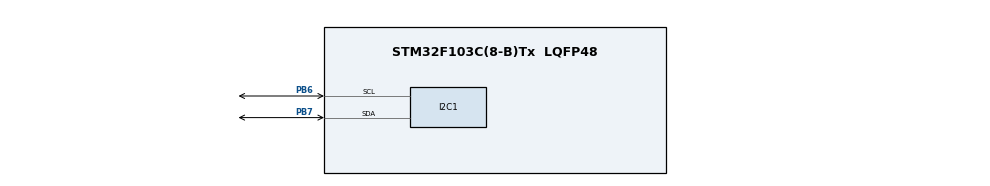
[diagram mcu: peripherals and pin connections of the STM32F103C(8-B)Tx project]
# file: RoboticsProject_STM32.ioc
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Mcu.Family=STM32F1
Mcu.Name=STM32F103C(8-B)Tx
Mcu.Package=LQFP48
NVIC.PriorityGroup=NVIC_PRIORITYGROUP_4
PA13.Mode=Serial_Wire
PA13.Signal=SYS_JTMS-SWDIO
PA14.Mode=Serial_Wire
PA14.Signal=SYS_JTCK-SWCLK
PB6.Mode=I2C
PB6.Signal=I2C1_SCL
PB7.Mode=I2C
PB7.Signal=I2C1_SDA
PD0-OSC_IN.Mode=HSE-External-Oscillator
PD0-OSC_IN.Signal=RCC_OSC_IN
PD1-OSC_OUT.Mode=HSE-External-Oscillator
PD1-OSC_OUT.Signal=RCC_OSC_OUT
ProjectManager.HeapSize=0x200
ProjectManager.StackSize=0x400
ProjectManager.TargetToolchain=STM32CubeIDE
RCC.APB1Freq_Value=8000000
RCC.APB2Freq_Value=8000000
board=custom

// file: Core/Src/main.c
/* USER CODE BEGIN Header */
/**
  ******************************************************************************
  * @file           : main.c
  * @brief          : Main program body
  ******************************************************************************
  * @attention
  *
  * Copyright (c) 2024 STMicroelectronics.
  * All rights reserved.
  *
  * This software is licensed under terms that can be found in the LICENSE file
  * in the root directory of this software component.
  * If no LICENSE file comes with this software, it is provided AS-IS.
  *
  ******************************************************************************
  */
/* USER CODE END Header */
/* USER CODE BEGIN Header */
/**
  ******************************************************************************
  * @file           : main.c
  * @brief          : Main program body
  ******************************************************************************
  * @attention
  *
  * Copyright (c) 2024 STMicroelectronics.
  * All rights reserved.
  *
  * This software is licensed under terms that can be found in the LICENSE file
  * in the root directory of this software component.
  * If no LICENSE file comes with this software, it is provided AS-IS.
  *
  ******************************************************************************
  */
/* USER CODE END Header */
#include "main.h"
#include <math.h>

/* USER CODE BEGIN PD */
#define PCA9685_ADDRESS 0x80
#define MPU6050_ADDR 0xD0
#define PCA9685_MODE1 0x00
#define PCA9685_PRE_SCALE 0xFE
#define PCA9685_LED0_ON_L 0x06
#define PCA9685_MODE1_SLEEP_BIT 4
#define PCA9685_MODE1_AI_BIT 5
#define PCA9685_MODE1_RESTART_BIT 7
#define NUM_SERVOS 5
/* USER CODE END PD */

I2C_HandleTypeDef hi2c1;
float Ax, Ay, Az, Gz;

void SystemClock_Config(void);
static void MX_GPIO_Init(void);
static void MX_I2C1_Init(void);

/* USER CODE BEGIN PFP */

void PCA9685_SetBit(uint8_t Register, uint8_t Bit, uint8_t Value);
void PCA9685_SetPWMFrequency(uint16_t frequency);
void PCA9685_Init(uint16_t frequency);
void PCA9685_SetPWM(uint8_t Channel, uint16_t OnTime, uint16_t OffTime);
void PCA9685_SetServoAngle(uint8_t Channel, float Angle);
void MPU6050_Init(void);
void MPU6050_Read_Accel(void);
void MPU6050_Read_Gyro(void);

/* USER CODE END PFP */

/* USER CODE BEGIN 0 */

void PCA9685_SetBit(uint8_t Register, uint8_t Bit, uint8_t Value)
{
    uint8_t readValue;
    HAL_I2C_Mem_Read(&hi2c1, PCA9685_ADDRESS, Register, 1, &readValue, 1, 10);
    if (Value == 0)
        readValue &= ~(1 << Bit);
    else
        readValue |= (1 << Bit);
    HAL_I2C_Mem_Write(&hi2c1, PCA9685_ADDRESS, Register, 1, &readValue, 1, 10);
    HAL_Delay(1);
}

void PCA9685_SetPWMFrequency(uint16_t frequency)
{
    uint8_t prescale = (uint8_t)((25000000 / (4096 * frequency)) - 1);
    PCA9685_SetBit(PCA9685_MODE1, PCA9685_MODE1_SLEEP_BIT, 1);
    HAL_I2C_Mem_Write(&hi2c1, PCA9685_ADDRESS, PCA9685_PRE_SCALE, 1, &prescale, 1, 10);
    PCA9685_SetBit(PCA9685_MODE1, PCA9685_MODE1_SLEEP_BIT, 0);
    PCA9685_SetBit(PCA9685_MODE1, PCA9685_MODE1_RESTART_BIT, 1);
}

void PCA9685_Init(uint16_t frequency)
{
    PCA9685_SetPWMFrequency(frequency);
    PCA9685_SetBit(PCA9685_MODE1, PCA9685_MODE1_AI_BIT, 1);
}

void PCA9685_SetPWM(uint8_t Channel, uint16_t OnTime, uint16_t OffTime)
{
    uint8_t registerAddress = PCA9685_LED0_ON_L + (4 * Channel);
    uint8_t pwm[4] = { OnTime & 0xFF, OnTime >> 8, OffTime & 0xFF, OffTime >> 8 };
    HAL_I2C_Mem_Write(&hi2c1, PCA9685_ADDRESS, registerAddress, 1, pwm, 4, 10);
}

void PCA9685_SetServoAngle(uint8_t Channel, float Angle)
{
    if (Angle < 0) Angle = 0;
    if (Angle > 180) Angle = 180;
    float Value = (Angle * (511.9 - 102.4) / 180.0) + 102.4;
    PCA9685_SetPWM(Channel, 0, (uint16_t)Value);
}

void MPU6050_Init(void)
{
    uint8_t check, Data;
    HAL_I2C_Mem_Read(&hi2c1, MPU6050_ADDR, 0x75, 1, &check, 1, 1000);
    if (check == 0x68)
    {
        Data = 0;
        HAL_I2C_Mem_Write(&hi2c1, MPU6050_ADDR, 0x6B, 1, &Data, 1, 1000);
        Data = 0x07;
        HAL_I2C_Mem_Write(&hi2c1, MPU6050_ADDR, 0x19, 1, &Data, 1, 1000);
        Data = 0x00;
        HAL_I2C_Mem_Write(&hi2c1, MPU6050_ADDR, 0x1B, 1, &Data, 1, 1000);
        Data = 0x00;
        HAL_I2C_Mem_Write(&hi2c1, MPU6050_ADDR, 0x1C, 1, &Data, 1, 1000);
    }
}

void MPU6050_Read_Accel(void)
{
    uint8_t Rec_Data[6];
    HAL_I2C_Mem_Read(&hi2c1, MPU6050_ADDR, 0x3B, 1, Rec_Data, 6, 1000);
    int16_t Accel_X_RAW = (int16_t)(Rec_Data[0] << 8 | Rec_Data[1]);
    int16_t Accel_Y_RAW = (int16_t)(Rec_Data[2] << 8 | Rec_Data[3]);
    int16_t Accel_Z_RAW = (int16_t)(Rec_Data[4] << 8 | Rec_Data[5]);

    Ax = (float)Accel_X_RAW / 16384.0;
    Ay = (float)Accel_Y_RAW / 16384.0;
    Az = (float)Accel_Z_RAW / 16384.0;
}

void MPU6050_Read_Gyro(void)
{
    uint8_t Rec_Data[6];
    HAL_I2C_Mem_Read(&hi2c1, MPU6050_ADDR, 0x43, 1, Rec_Data, 6, 1000);
    int16_t Gyro_X_RAW = (uint16_t)(Rec_Data[0] << 8 | Rec_Data[1]);
    int16_t Gyro_Y_RAW = (uint16_t)(Rec_Data[2] << 8 | Rec_Data[3]);
    int16_t Gyro_Z_RAW = (int16_t)(Rec_Data[4] << 8 | Rec_Data[5]);

    Gz = (float)Gyro_Z_RAW / 131.0;
}

/* USER CODE END 0 */

int main(void)
{
    HAL_Init();
    SystemClock_Config();
    MX_GPIO_Init();
    MX_I2C1_Init();

    MPU6050_Init();
    PCA9685_Init(50);

    while (1)
    {
        MPU6050_Read_Accel();
        MPU6050_Read_Gyro();

        float roll = atan2(Ay, Az) * 180.0 / M_PI;
        float pitch = atan2(-Ax, sqrt(Ay * Ay + Az * Az)) * 180.0 / M_PI;
        float yaw = Gz;

        PCA9685_SetServoAngle(0, roll);
        PCA9685_SetServoAngle(1, pitch);
        PCA9685_SetServoAngle(2, yaw);
        PCA9685_SetServoAngle(3, roll);
        PCA9685_SetServoAngle(4, pitch);

        HAL_Delay(100);
    }
}

void SystemClock_Config(void)
{
  RCC_OscInitTypeDef RCC_OscInitStruct = {0};
  RCC_ClkInitTypeDef RCC_ClkInitStruct = {0};

  /** Initializes the RCC Oscillators according to the specified parameters
  * in the RCC_OscInitTypeDef structure.
  */
  RCC_OscInitStruct.OscillatorType = RCC_OSCILLATORTYPE_HSI;
  RCC_OscInitStruct.HSIState = RCC_HSI_ON;
  RCC_OscInitStruct.HSICalibrationValue = RCC_HSICALIBRATION_DEFAULT;
  RCC_OscInitStruct.PLL.PLLState = RCC_PLL_NONE;
  if (HAL_RCC_OscConfig(&RCC_OscInitStruct) != HAL_OK)
  {
    Error_Handler();
  }

  /** Initializes the CPU, AHB and APB buses clocks
  */
  RCC_ClkInitStruct.ClockType = RCC_CLOCKTYPE_HCLK|RCC_CLOCKTYPE_SYSCLK
                              |RCC_CLOCKTYPE_PCLK1|RCC_CLOCKTYPE_PCLK2;
  RCC_ClkInitStruct.SYSCLKSource = RCC_SYSCLKSOURCE_HSI;
  RCC_ClkInitStruct.AHBCLKDivider = RCC_SYSCLK_DIV1;
  RCC_ClkInitStruct.APB1CLKDivider = RCC_HCLK_DIV1;
  RCC_ClkInitStruct.APB2CLKDivider = RCC_HCLK_DIV1;

  if (HAL_RCC_ClockConfig(&RCC_ClkInitStruct, FLASH_LATENCY_0) != HAL_OK)
  {
    Error_Handler();
  }
}

static void MX_I2C1_Init(void)
{

  hi2c1.Instance = I2C1;
  hi2c1.Init.ClockSpeed = 100000;
  hi2c1.Init.DutyCycle = I2C_DUTYCYCLE_2;
  hi2c1.Init.OwnAddress1 = 0;
  hi2c1.Init.AddressingMode = I2C_ADDRESSINGMODE_7BIT;
  hi2c1.Init.DualAddressMode = I2C_DUALADDRESS_DISABLE;
  hi2c1.Init.OwnAddress2 = 0;
  hi2c1.Init.GeneralCallMode = I2C_GENERALCALL_DISABLE;
  hi2c1.Init.NoStretchMode = I2C_NOSTRETCH_DISABLE;
  if (HAL_I2C_Init(&hi2c1) != HAL_OK)
  {
    Error_Handler();
  }

}

static void MX_GPIO_Init(void)
{

  /* GPIO Ports Clock Enable */
  __HAL_RCC_GPIOD_CLK_ENABLE();
  __HAL_RCC_GPIOA_CLK_ENABLE();
  __HAL_RCC_GPIOB_CLK_ENABLE();

}

void Error_Handler(void)
{
  __disable_irq();
  while (1)
  {
  }
}
